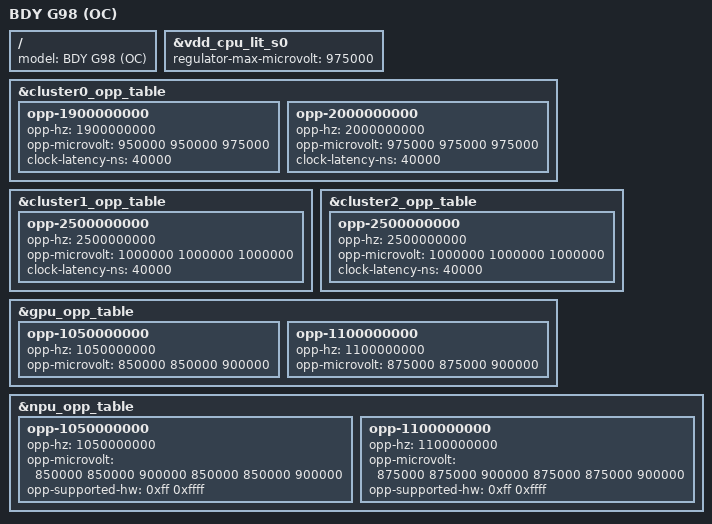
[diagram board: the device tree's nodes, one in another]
// SPDX-License-Identifier: (GPL-2.0+ OR MIT)
/*
 * BDY G98 overclock variant.
 */

#include "rk3588-bdy-g98.dts"

/ {
	model = "BDY G98 (OC)";
};

/*
 * Raise little-core rail ceiling for the 1.9/2.0 GHz OPPs below
 * rk3588-rk806-single.dtsi default: 950 mV
 */
&vdd_cpu_lit_s0 {
	regulator-max-microvolt = <975000>;
};

/* ===== CPU/GPU/NPU overclock OPPs ===== */
&cluster0_opp_table {
	opp-1900000000 {
		opp-hz = /bits/ 64 <1900000000>;
		opp-microvolt = <950000 950000 975000>;
		clock-latency-ns = <40000>;
	};
	opp-2000000000 {
		opp-hz = /bits/ 64 <2000000000>;
		opp-microvolt = <975000 975000 975000>;
		clock-latency-ns = <40000>;
	};
};

&cluster1_opp_table {
	opp-2500000000 {
		opp-hz = /bits/ 64 <2500000000>;
		opp-microvolt = <1000000 1000000 1000000>;
		clock-latency-ns = <40000>;
	};
};

&cluster2_opp_table {
	opp-2500000000 {
		opp-hz = /bits/ 64 <2500000000>;
		opp-microvolt = <1000000 1000000 1000000>;
		clock-latency-ns = <40000>;
	};
};

&gpu_opp_table {
	opp-1050000000 {
		opp-hz = /bits/ 64 <1050000000>;
		opp-microvolt = <850000 850000 900000>;
	};

	opp-1100000000 {
		opp-hz = /bits/ 64 <1100000000>;
		opp-microvolt = <875000 875000 900000>;
	};
};

&npu_opp_table {
	opp-1050000000 {
		opp-hz = /bits/ 64 <1050000000>;
		opp-microvolt = <850000 850000 900000 850000 850000 900000>;
		opp-supported-hw = <0xff 0xffff>;
	};

	opp-1100000000 {
		opp-hz = /bits/ 64 <1100000000>;
		opp-microvolt = <875000 875000 900000 875000 875000 900000>;
		opp-supported-hw = <0xff 0xffff>;
	};
};
